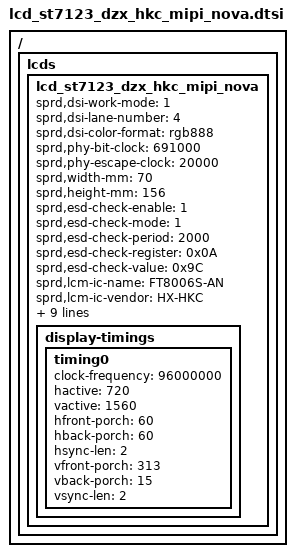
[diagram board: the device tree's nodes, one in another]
/ { lcds {
	lcd_st7123_dzx_hkc_mipi_nova: lcd_st7123_dzx_hkc_mipi_nova {

		sprd,dsi-work-mode = <1>;
		sprd,dsi-lane-number = <4>;
		sprd,dsi-color-format = "rgb888";

		sprd,phy-bit-clock = <691000>;
		sprd,phy-escape-clock = <20000>;

		sprd,width-mm = <70>;
		sprd,height-mm = <156>;

		sprd,esd-check-enable = <1>;
		sprd,esd-check-mode = <1>;
		sprd,esd-check-period = <2000>;
		sprd,esd-check-register = <0x0A>;
		sprd,esd-check-value = <0x9C>;
		
		sprd,lcm-ic-name = "FT8006S-AN";
		sprd,lcm-ic-vendor = "HX-HKC";
		sprd,lcm-ic-inch = "6.3";
		
		sprd,reset-on-sequence = <1 10>, <0 10>, <1 50>;
		sprd,reset-off-sequence = <1 5>;

		sprd,initial-command = [				
			29 00 00 04 60 71 23 a2
			29 00 00 04 60 71 23 a3
			29 00 00 04 60 71 23 a4
			23 00 00 02 CF 18
			29 00 00 07 85 48 87 E7 04 87 46
			29 00 00 0d 86 A5 19 40 15 F5 01 00 A5 D9 55 F5 0D
			29 00 00 07 d7 00 11 D6 BB 0c 0c
			29 00 00 10 B2 15 19 05 23 41 FF 03 52 62 D2 FF 10 20 E9 10
			29 00 00 06 E8 20 6A 04 7B 7B
			29 00 00 07 b7 00 00 72 72 44 1A
			29 00 00 08 B0 22 57 11 75 25 2F 39  
			29 00 00 28 A3 88 01 8C A0 45 00 00 00 00 00 46 00 00 1E 5C 1E 80 00 6F 45 00 00 00 00 00 46 00 00 1E 5C 1E 80 00 20 58 00 00 00 FF
			29 00 00 33 A6 5F 18 24 55 36 00 00 03 43 43 91 FF 08 24 55 37 00 00 02 43 43 91 FF 58 E4 55 07 07 07 09 43 43 91 FF 07 DB 55 07 07 07 09 43 43 FF FF 00 08 80 08 80
			29 00 00 3d A7 19 19 81 64 40 07 16 40 00 40 03 43 43 91 FF 08 88 64 40 25 34 40 00 02 01 43 43 91 FF 08 88 64 00 4B C3 46 0E 0D 05 FF 90 91 FF 00 80 64 00 69 E1 08 10 2B 03 FF 90 91 FF F0 80 44
			29 00 00 29 AC 00 00 00 00 04 04 01 18 19 06 09 0B 12 10 02 00 00 00 00 00 00 00 00 00 00 00 04 04 03 18 19 06 08 0A 13 11 00 00 00 00
			29 00 00 1a AD 00 00 46 07 07 00 00 ff ff 00 00 02 00 00 00 00 ff ff 01 00 00 ff ff ff ff
			29 00 00 08 AE F0 7F 00 F0 7F 00 00
			29 00 00 0b A9 00 00 73 FF 00 02 00 00 02 00 
			29 00 00 25 e7 3B 00 00 7C A1 8C 20 1A F0 B1 50 00 50 B1 50 B1 50 D8 00 55 00 B1 00 45 C9 6A FF 5A D8 38 88 15 B1 01 01 71
			29 00 00 0b EA 16 00 FF 01 01 86 01 1E 80 40
			23 00 00 02 75 29
			29 00 00 03 89 00 00
			23 00 00 02 BF 8d
			29 00 00 26 C8 00 00 0B 11 21 00 3A 00 7B 05 10 DE 08 58 04 11 AF 01 F8 0F 22 3D 0D 8C 09 32 FF 0A 5E 0D F3 A9 05 D2 EF 03 FC
			29 00 00 26 C9 00 00 0B 11 21 00 3A 00 7B 05 10 DE 08 58 04 11 AF 01 F8 0F 22 3D 0D 8C 09 32 FF 0A 5E 0D F3 A9 05 D2 EF 03 FC
			23 00 00 02 35 00
			13 78 00 01 11
			13 10 00 01 29
		];
		sprd,sleep-in-command = [
			13 0A 00 01 28
			13 78 00 01 10		
		];
		sprd,sleep-out-command = [
			13 78 00 01 11
			13 10 00 01 29
		];

		display-timings {
			timing0{
				clock-frequency = <96000000>;
				hactive = <720>;
				vactive = <1560>;
				hfront-porch = <60>;
				hback-porch = <60>;
				hsync-len = <2>;
				vfront-porch = <313>;
				vback-porch = <15>;
				vsync-len = <2>;
			};
		};
	};
};};


